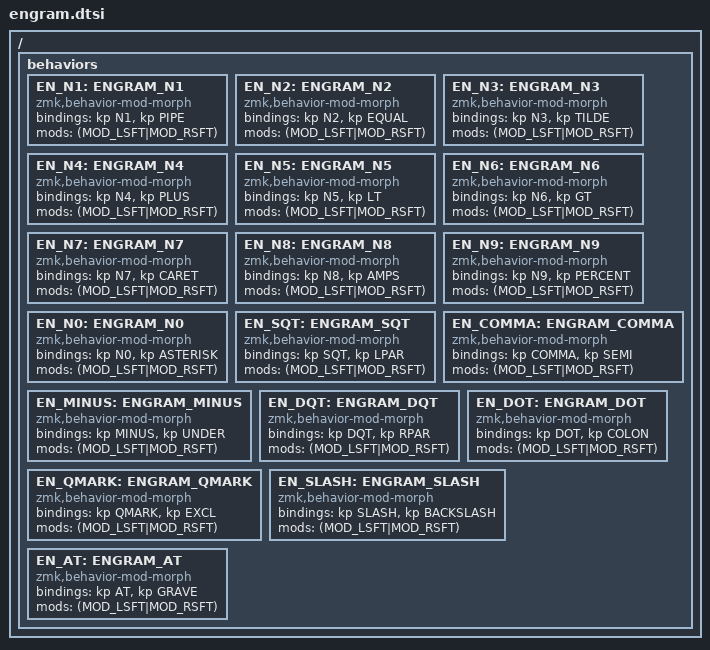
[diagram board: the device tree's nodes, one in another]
#include <behaviors.dtsi>
#include <dt-bindings/zmk/keys.h>

/ {
    behaviors {
        /omit-if-no-ref/ EN_N1: ENGRAM_N1 {
        compatible = "zmk,behavior-mod-morph";
        #binding-cells = <0>;
                bindings = <&kp N1>, <&kp PIPE>;
        mods = <(MOD_LSFT|MOD_RSFT)>;
        };

        /omit-if-no-ref/ EN_N2: ENGRAM_N2 {
        compatible = "zmk,behavior-mod-morph";
        #binding-cells = <0>;
                bindings = <&kp N2>, <&kp EQUAL>;
        mods = <(MOD_LSFT|MOD_RSFT)>;
        };

        /omit-if-no-ref/ EN_N3: ENGRAM_N3 {
        compatible = "zmk,behavior-mod-morph";
        #binding-cells = <0>;
                bindings = <&kp N3>, <&kp TILDE>;
        mods = <(MOD_LSFT|MOD_RSFT)>;
        };

        /omit-if-no-ref/ EN_N4: ENGRAM_N4 {
        compatible = "zmk,behavior-mod-morph";
        #binding-cells = <0>;
                bindings = <&kp N4>, <&kp PLUS>;
        mods = <(MOD_LSFT|MOD_RSFT)>;
        };

        /omit-if-no-ref/ EN_N5: ENGRAM_N5 {
        compatible = "zmk,behavior-mod-morph";
        #binding-cells = <0>;
                bindings = <&kp N5>, <&kp LT>;
        mods = <(MOD_LSFT|MOD_RSFT)>;
        };

        /omit-if-no-ref/ EN_N6: ENGRAM_N6 {
        compatible = "zmk,behavior-mod-morph";
        #binding-cells = <0>;
                bindings = <&kp N6>, <&kp GT>;
        mods = <(MOD_LSFT|MOD_RSFT)>;
        };

        /omit-if-no-ref/ EN_N7: ENGRAM_N7 {
        compatible = "zmk,behavior-mod-morph";
        #binding-cells = <0>;
                bindings = <&kp N7>, <&kp CARET>;
        mods = <(MOD_LSFT|MOD_RSFT)>;
        };

        /omit-if-no-ref/ EN_N8: ENGRAM_N8 {
        compatible = "zmk,behavior-mod-morph";
        #binding-cells = <0>;
                bindings = <&kp N8>, <&kp AMPS>;
        mods = <(MOD_LSFT|MOD_RSFT)>;
        };

        /omit-if-no-ref/ EN_N9: ENGRAM_N9 {
        compatible = "zmk,behavior-mod-morph";
        #binding-cells = <0>;
                bindings = <&kp N9>, <&kp PERCENT>;
        mods = <(MOD_LSFT|MOD_RSFT)>;
        };

        /omit-if-no-ref/ EN_N0: ENGRAM_N0 {
        compatible = "zmk,behavior-mod-morph";
        #binding-cells = <0>;
                bindings = <&kp N0>, <&kp ASTERISK>;
        mods = <(MOD_LSFT|MOD_RSFT)>;
        };

        /omit-if-no-ref/ EN_SQT: ENGRAM_SQT {
        compatible = "zmk,behavior-mod-morph";
        #binding-cells = <0>;
                bindings = <&kp SQT>, <&kp LPAR>;
        mods = <(MOD_LSFT|MOD_RSFT)>;
        };

        /omit-if-no-ref/ EN_COMMA: ENGRAM_COMMA {
        compatible = "zmk,behavior-mod-morph";
        #binding-cells = <0>;
                bindings = <&kp COMMA>, <&kp SEMI>;
        mods = <(MOD_LSFT|MOD_RSFT)>;
        };

        /omit-if-no-ref/ EN_MINUS: ENGRAM_MINUS {
        compatible = "zmk,behavior-mod-morph";
        #binding-cells = <0>;
                bindings = <&kp MINUS>, <&kp UNDER>;
        mods = <(MOD_LSFT|MOD_RSFT)>;
        };

        /omit-if-no-ref/ EN_DQT: ENGRAM_DQT {
        compatible = "zmk,behavior-mod-morph";
        #binding-cells = <0>;
                bindings = <&kp DQT>, <&kp RPAR>;
        mods = <(MOD_LSFT|MOD_RSFT)>;
        };

        /omit-if-no-ref/ EN_DOT: ENGRAM_DOT {
        compatible = "zmk,behavior-mod-morph";
        #binding-cells = <0>;
                bindings = <&kp DOT>, <&kp COLON>;
        mods = <(MOD_LSFT|MOD_RSFT)>;
        };

        /omit-if-no-ref/ EN_QMARK: ENGRAM_QMARK {
        compatible = "zmk,behavior-mod-morph";
        #binding-cells = <0>;
                bindings = <&kp QMARK>, <&kp EXCL>;
        mods = <(MOD_LSFT|MOD_RSFT)>;
        };

        /omit-if-no-ref/ EN_SLASH: ENGRAM_SLASH {
        compatible = "zmk,behavior-mod-morph";
        #binding-cells = <0>;
                bindings = <&kp SLASH>, <&kp BACKSLASH>;
        mods = <(MOD_LSFT|MOD_RSFT)>;
        };

        /omit-if-no-ref/ EN_AT: ENGRAM_AT {
        compatible = "zmk,behavior-mod-morph";
        #binding-cells = <0>;
                bindings = <&kp AT>, <&kp GRAVE>;
        mods = <(MOD_LSFT|MOD_RSFT)>;
        };
    };
};
